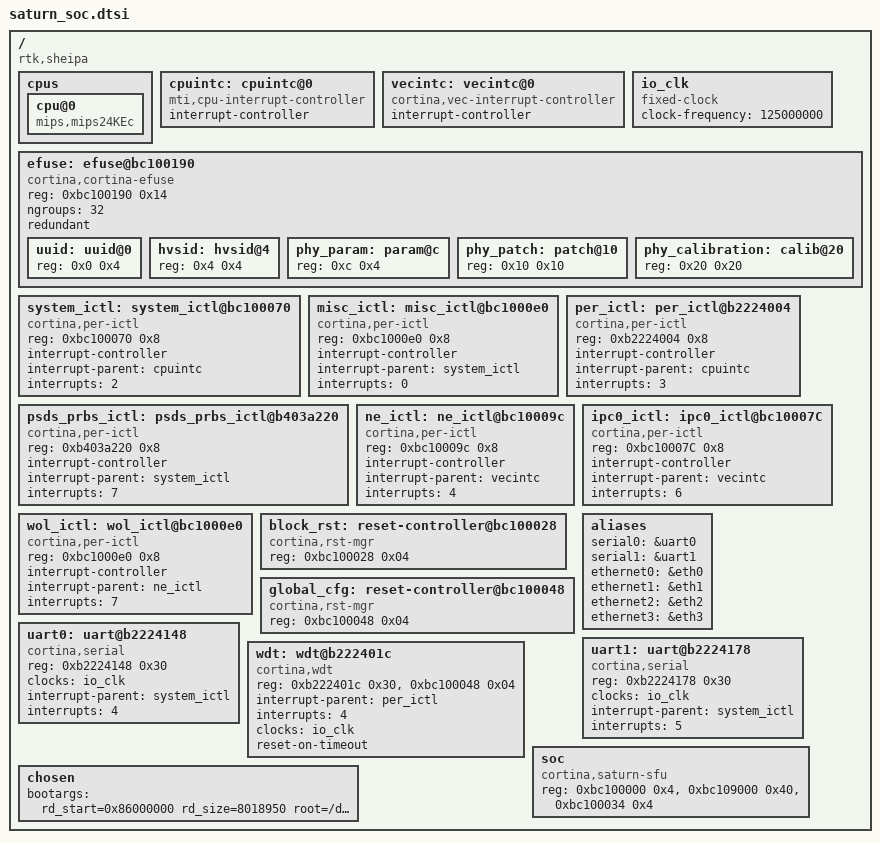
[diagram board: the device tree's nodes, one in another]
/*
 * Copyright (c) 2015-2017, Cortina Access. All rights reserved.
 *
 * Redistribution and use in source and binary forms, with or without
 * modification, are permitted provided that the following conditions are met:
 *
 * Redistributions of source code must retain the above copyright notice, this
 * list of conditions and the following disclaimer.
 *
 * Redistributions in binary form must reproduce the above copyright notice,
 * this list of conditions and the following disclaimer in the documentation
 * and/or other materials provided with the distribution.
 *
 * THIS SOFTWARE IS PROVIDED BY THE COPYRIGHT HOLDERS AND CONTRIBUTORS "AS IS"
 * AND ANY EXPRESS OR IMPLIED WARRANTIES, INCLUDING, BUT NOT LIMITED TO, THE
 * IMPLIED WARRANTIES OF MERCHANTABILITY AND FITNESS FOR A PARTICULAR PURPOSE
 * ARE DISCLAIMED. IN NO EVENT SHALL THE COPYRIGHT HOLDER OR CONTRIBUTORS BE
 * LIABLE FOR ANY DIRECT, INDIRECT, INCIDENTAL, SPECIAL, EXEMPLARY, OR
 * CONSEQUENTIAL DAMAGES (INCLUDING, BUT NOT LIMITED TO, PROCUREMENT OF
 * SUBSTITUTE GOODS OR SERVICES; LOSS OF USE, DATA, OR PROFITS; OR BUSINESS
 * INTERRUPTION) HOWEVER CAUSED AND ON ANY THEORY OF LIABILITY, WHETHER IN
 * CONTRACT, STRICT LIABILITY, OR TORT (INCLUDING NEGLIGENCE OR OTHERWISE)
 * ARISING IN ANY WAY OUT OF THE USE OF THIS SOFTWARE, EVEN IF ADVISED OF THE
 * POSSIBILITY OF SUCH DAMAGE.
 */

#include <dt-bindings/interrupt-controller/irq.h>
#include <dt-bindings/soc/cortina_glb_cfg.h>

/ {
	compatible = "rtk,sheipa";
	#address-cells = <1>;
	#size-cells = <1>;

	cpus {
		#address-cells = <1>;
		#size-cells = <0>;

		cpu@0 {
			compatible = "mips,mips24KEc";
		};
	};

	cpuintc: cpuintc@0 {
		#address-cells = <0>;
		#interrupt-cells = <1>;
		interrupt-controller;
		compatible = "mti,cpu-interrupt-controller";
	};

    vecintc: vecintc@0 {
		#address-cells = <0>;
		#interrupt-cells = <1>;
		interrupt-controller;
		compatible = "cortina,vec-interrupt-controller";
    };
	/* APB clock varies based */
	/* TODO: develop clock driver to switch between freq. for now use fixed freq. */
	io_clk: io_clk {
		compatible = "fixed-clock";
		#clock-cells = <0>;
		clock-frequency = <125000000>;
	};
	
        efuse: efuse@bc100190 {
                compatible = "cortina,cortina-efuse";
                #address-cells = <1>;
                #size-cells = <1>;
                reg = <0xbc100190 0x14>;
                ngroups = <32>;
                redundant;

                uuid: uuid@0 {
                        reg = <0x0 0x4>;
                };
                hvsid: hvsid@4 {
                        reg = <0x4 0x4>;
                };
                phy_param: param@c {
                        reg = <0xc 0x4>;
                };
                phy_patch: patch@10 {
                        reg = <0x10 0x10>;
                };
                phy_calibration: calib@20 {
                        reg = <0x20 0x20>;
                };
        };
	system_ictl: system_ictl@bc100070 {	/* System interrupt */
				compatible = "cortina,per-ictl";
				reg = <0xbc100070  0x8>;
				interrupt-controller;
				#interrupt-cells = <1>;
				interrupt-parent = <&cpuintc>;
				interrupts = <2>;
	};

	misc_ictl: misc_ictl@bc1000e0 {	/* System interrupt */
				compatible = "cortina,per-ictl";
				reg = <0xbc1000e0  0x8>;
				interrupt-controller;
				#interrupt-cells = <1>;
				interrupt-parent = <&system_ictl>;
				interrupts = <0>;
	};

	psds_prbs_ictl: psds_prbs_ictl@b403a220 { /* PRBS interrupt */
				compatible = "cortina,per-ictl";
				reg = <0xb403a220 0x8>;
				interrupt-controller;
				#interrupt-cells = <1>;
				interrupt-parent = <&system_ictl>;
				interrupts = <7>;
	};

	per_ictl: per_ictl@b2224004 {	/* peripheral interrupt */
				compatible = "cortina,per-ictl";
				reg = <0xb2224004  0x8>;
				interrupt-controller;
				#interrupt-cells = <1>;
				interrupt-parent = <&cpuintc>;
				interrupts = <3>;
	};


	ne_ictl: ne_ictl@bc10009c {	/* NE interrupt */
				compatible = "cortina,per-ictl";
				reg = <0xbc10009c  0x8>;
				interrupt-controller;
				#interrupt-cells = <1>;
				interrupt-parent = <&vecintc>;
				interrupts = <4>;	/* vector driver handle it as x+VEC_BASE */
	};
	


	ipc0_ictl: ipc0_ictl@bc10007C {	/* IPC  interrupt */
				compatible = "cortina,per-ictl";
				reg = <0xbc10007C 0x8>;
				interrupt-controller;
				#interrupt-cells = <1>;
				interrupt-parent = <&vecintc>;
				interrupts = <6>;	/* vector driver handle it as x+VEC_BASE */
	};

	wol_ictl: wol_ictl@bc1000e0 {	/* Wake on LAN interrupt */
				compatible = "cortina,per-ictl";
				reg = <0xbc1000e0  0x8>;
				interrupt-controller;
				#interrupt-cells = <1>;
				interrupt-parent = <&ne_ictl>;
				interrupts = <7>;
	};


	/* Block Reset */
	block_rst: reset-controller@bc100028 {
		compatible = "cortina,rst-mgr";
		reg = <0xbc100028 0x04>;
		#reset-cells = <1>;
	};

	/* Global Config */
	global_cfg: reset-controller@bc100048 {
		compatible = "cortina,rst-mgr";
		reg = <0xbc100048 0x04>;
		#reset-cells = <1>;
	};

	aliases {
		serial0 = &uart0;
		serial1 = &uart1;
		ethernet0 = &eth0;
		ethernet1 = &eth1;
		ethernet2 = &eth2;
		ethernet3 = &eth3;
	};

	uart0: uart@b2224148 { /* console */
		device_type = "serial";
		compatible = "cortina,serial";
		reg = <0xb2224148 0x30>;
		clocks = <&io_clk>;
		interrupt-parent = <&system_ictl>;
		interrupts = <4>;
	};

	uart1: uart@b2224178 { /* console */
		device_type = "serial";
		compatible = "cortina,serial";
		reg = <0xb2224178 0x30>;
		clocks = <&io_clk>;
		interrupt-parent = <&system_ictl>;
		interrupts = <5>;
	};

	wdt: wdt@b222401c {
		compatible = "cortina,wdt";
		reg = <0xb222401c 0x30>,
			<0xbc100048 0x04>;
		interrupt-parent = <&per_ictl>;
		interrupts = <4>;
		clocks = <&io_clk>;
		reset-on-timeout;
	};


	soc {
		compatible = "cortina,saturn-sfu";
		reg = <0xbc100000 0x4>,		/* GLOBAL_JTAG_ID */
		      <0xbc109000 0x40>,	/* CLKGEN_CLKGEN_CONFIG */
		      <0xbc100034 0x4>;		/* GLOBAL_STRAP */
		reg-names = "JTAG_ID", "CLOCK", "STRAP";
	};

	chosen {
		/*TODO: need modfiy according to ramdisk at uboot stage */
		bootargs = "rd_start=0x86000000 rd_size=8018950 root=/dev/ram console=ttyS0,115200 rdinit=/sbin/init ";
	};
};
